# RL6678_IP_SVD register map
Vendor: Realtek
Registers are 32-bit, read-write, reset 0x0 unless marked. A register's access mark holds for its fields unless they carry their own. Offsets are from the block's base; [hi:lo] are bit positions; {n}, {i} and the like mark numbered series; 'fields as' and 'values as' point back to an identical list; <NAME> marks a mode.

## DDRPHY_REG (part 1 of 2)
Base 0x41011000
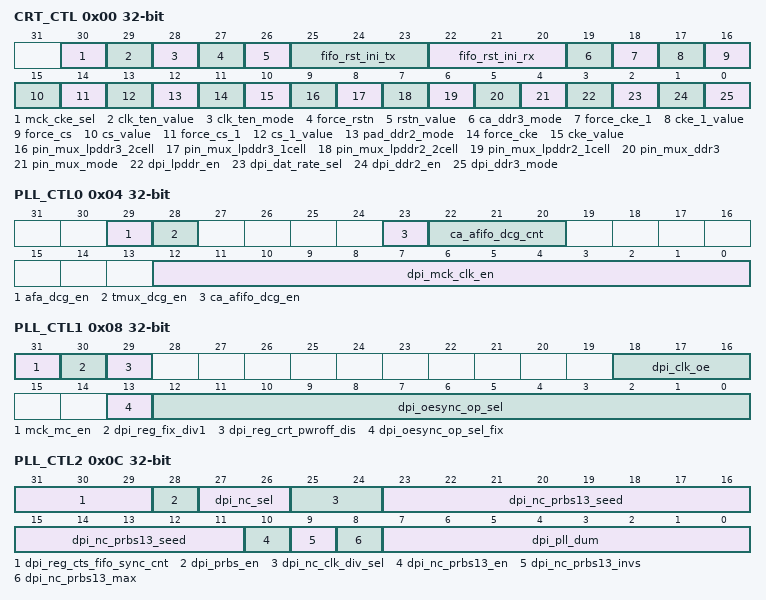
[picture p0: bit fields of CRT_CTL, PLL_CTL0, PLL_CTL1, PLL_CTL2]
0x00 CRT_CTL
  [30] mck_cke_sel — 1'b0 : mck_cke = mck_ca 1'b1 : mck_cke = mck_cs
  [29] clk_ten_value — Value for ten mode of clk
  [28] clk_ten_mode — 1 for ten mode
  [27] force_rstn — 1 for forcing PAD_DDR_RSTN value to rstn_value
  [26] rstn_value — Value of PAD_DDR_RSTN when force_rstn = 1
  [25:23] fifo_rst_ini_tx — Initial value of Tx CTS FIFO read point
  [22:20] fifo_rst_ini_rx — Initial value of Rx CTS FIFO read point
  [19] ca_ddr3_mode — Connect to command/address pad's DDR3_MODE
  [18] force_cke_1 — 1 for forcing PAD_DDR_CKE_1 value to cke_1_value
  [17] cke_1_value — Value of PAD_DDR_CKE_1 when force_cke_1 = 1
  [16] force_cs — 1 for forcing PAD_DDR_CS_N value to cs_value
  [15] cs_value — Value of PAD_DDR_CS_N when force_cs = 1
  [14] force_cs_1 — 1 for forcing PAD_DDR_CS_1_N value to cs_1_value
  [13] cs_1_value — Value of PAD_DDR_CS_1_N when force_cs_1 = 1
  [12] pad_ddr2_mode — Connect to P_PAD_DDR_VREF 0 : DDR3_MODE 1 : DDR2 MODE
  [11] force_cke — 1 for forcing PAD_DDR_CKE value to cke_value
  [10] cke_value — Value of PAD_DDR_CKE when force_cke = 1
  [9] pin_mux_lpddr3_2cell — DDR3 : b0_0001 DDR2 : b0_1000
  [8] pin_mux_lpddr3_1cell — DDR3 : b0_0001 DDR2 : b0_1000
  [7] pin_mux_lpddr2_2cell — DDR3 : b0_0001 DDR2 : b0_1000
  [6] pin_mux_lpddr2_1cell — DDR3 : b0_0001 DDR2 : b0_1000
  [5] pin_mux_ddr3 — DDR3 : b0_0001 DDR2 : b0_1000
  [4] pin_mux_mode — 1'b1 : pin_mux bypass mode 1'b0 : pin_mux mode
  [3] dpi_lpddr_en — 1'b1 : LPDDR mode enable
  [2] dpi_dat_rate_sel — 1'b0 : 2to1 mode mck_cmd = mck_mc = 1/2 DCK 1'b1 : 1to1 mode mck_cmd = mck_mc = DCK
  [1] dpi_ddr2_en — ddr2_en=1 & ddr3_mod=1 DDR2(LPDDR2) mode ddr2_en=0 & ddr3_mod=1 DDR3(LPDDR3) mode ddr2_en=0 & ddr3_mod=0 DDR4 mode
  [0] dpi_ddr3_mode — ddr2_en=1 & ddr3_mod=1 DDR2(LPDDR2) mode ddr2_en=0 & ddr3_mod=1 DDR3(LPDDR3) mode ddr2_en=0 & ddr3_mod=0 DDR4 mode
0x04 PLL_CTL0
  [29] afa_dcg_en — Rx Alpha eye calibration clock gating enable
  [28] tmux_dcg_en — Bist test mux clock gating enable
  [23] ca_afifo_dcg_en — CA AFIFO clock gating enable
  [22:20] ca_afifo_dcg_cnt — CA AFIFO clock gating count = {ca_afifo_dcg_cnt, 2'b11}
  [12:0] dpi_mck_clk_en — DDR_PHY internal clock ICG enable ck_en[12:0] :clock enable ck_en[0]: mck_ck ck_en[1]: mck_cmd ck_en[2]: mck_dqs_0 ck_en[3]: mck_dqs_1 ck_en[4]: mck_dqs_2 (No use) ck_en[5]: mck_dqs_3 (No use) ck_en[6]: mck_dq_0 ck_en[7]: mck_dq_1 ck_en[8]: mck_dq_2 (No use) ck_en[9]: mck_dq_3 (No use) ck_en[10]: mck_cs ck_en[11]: mck_cs_1 (No use) ck_en[12]: mck_ck_1 (No use)
0x08 PLL_CTL1
  [31] mck_mc_en — 0: gated mck_mc to low
  [30] dpi_reg_fix_div1 — PLL sync CLK_OE clk is fix div1(1) or div2 (0 default)
  [29] dpi_reg_crt_pwroff_dis — clk_oe to PLL is from crt table or FSM, default is from crt table.
  [18:16] dpi_clk_oe — clk_oe[2:0]: PLL clock output enable clk_oe[0]:mck_ck clk_oe[1]: mck_cmd , mck_dqs_0, mck_dqs_1, mck_dqs_2, mck_dqs_3, mck_dq_0, mck_dq_1, mck_dq_2, mck_dq_3 clk_oe[2]: mck_ck_1
  [13] dpi_oesync_op_sel_fix — free run fix clock op_sel
  [12:0] dpi_oesync_op_sel — control signal for output clock enable sync op_sel[0]:mck_ck op_sel[1]:mck_cmd op_sel[2]:mck_dqs_0 op_sel[3]:mck_dqs_1 op_sel[4]:mck_dqs_2 op_sel[5]:mck_dqs_3 op_sel[6]:mck_dq_0 op_sel[7]:mck_dq_1 op_sel[8]:mck_dq_2 op_sel[9]:mck_dq_3 op_sel[10]:mck_cs op_sel[11]:mck_cs_1 op_sel[12]:mck_ck_1
0x0C PLL_CTL2
  [31:29] dpi_reg_cts_fifo_sync_cnt — sync cts fifo tx/rx pointer,wait cycles when pweroff_rst_n sync from tx to rx
  [28] dpi_prbs_en — PLL Noise Generator Enable
  [27:26] dpi_nc_sel — PLL Noise Generator noise current control
  [25:24] dpi_nc_clk_div_sel — Noise Generator clock select
  [23:11] dpi_nc_prbs13_seed — Noise Generator PRBS SEED
  [10] dpi_nc_prbs13_en — Noise Generator enable
  [9] dpi_nc_prbs13_invs — Noise Generator PRBS INVS
  [8] dpi_nc_prbs13_max — Noise Generator PRBS MAX
  [7:0] dpi_pll_dum — dummy Register
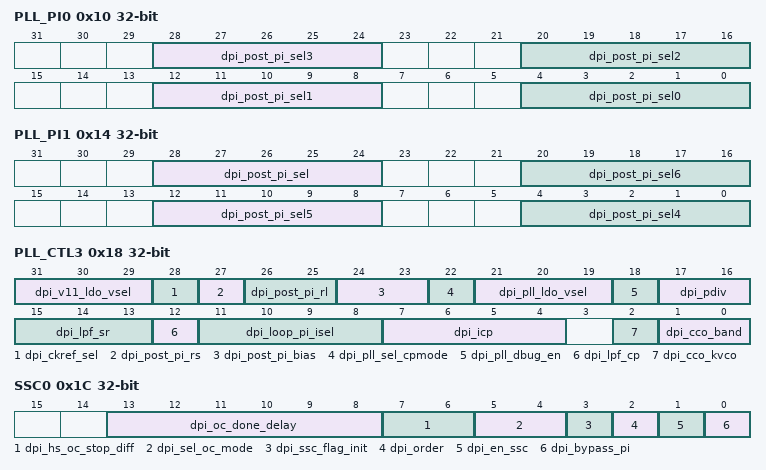
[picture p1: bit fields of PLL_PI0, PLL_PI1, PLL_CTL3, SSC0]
0x10 PLL_PI0
  [28:24] dpi_post_pi_sel3 — PLL phase select for mck_dqs_1
  [20:16] dpi_post_pi_sel2 — PLL phase select for mck_dqs_0
  [12:8] dpi_post_pi_sel1 — PLL phase select for mck_cmd
  [4:0] dpi_post_pi_sel0 — PLL phase select for mck_ck
0x14 PLL_PI1
  [28:24] dpi_post_pi_sel — PLL internal clock phase select
  [20:16] dpi_post_pi_sel6 — PLL phase select for mck_dq_0
  [12:8] dpi_post_pi_sel5 — PLL phase select for mck_dqs_3
  [4:0] dpi_post_pi_sel4 — PLL phase select for mck_dqs_2
0x18 PLL_CTL3
  [31:29] dpi_v11_ldo_vsel — Select PLL 1.0V LDO output 000: tracking digital core power 001: 0.85V; 010: 0.9V; 011: 1.0V; 100: 1.05V; 101: 1.1V 110: 1.15V 111: 1.2V
  [28] dpi_ckref_sel — Ref Clock select 1'b0: use CKREF_PAD 1'b1: use CKREF_TOP
  [27] dpi_post_pi_rs — Post PI loading cap control: 0: 112.5fF; 1: 15fF
  [26:25] dpi_post_pi_rl — Post PI RL control, changed with PLL freq: 00:0.2G~0.5G; 01:0.5G~0.8G; 10:0.8G~1.25G
  [24:23] dpi_post_pi_bias — Post PI bias current, changed with PLL freq: 00:0.2G~0.5G; 01:0.5G~0.8G; 10:0.8G~1.25G
  [22] dpi_pll_sel_cpmode — PLL charge pump mode selector, always set 1
  [21:19] dpi_pll_ldo_vsel — Select PLL 1.0V LDO output; 000: tracking core power; 001: 0.85V; 010: 0.9V; 011: 1.0V; 100: 1.05V; 101: 1.1V 110: 1.15V 111: 1.2V
  [18] dpi_pll_dbug_en — Enable PLL debug mode
  [17:16] dpi_pdiv — PLL pre-divider divisor register 00: /1; 01: /2; 10: /4; 11: /8
  [15:13] dpi_lpf_sr — PLL LPF resistor selector Register for LPF RS, combined used with REG_ICP and REG_LPF_CP to tune PLL bandwidth
  [12] dpi_lpf_cp — Register for LPF CP, combined used with REG_ICP and REG_LPF_SR to tune PLL bandwidth
  [11:8] dpi_loop_pi_isel — Select loop pi current, changed with PLL freq: 0010:0.2G~0.4G; 0011:0.4G~0.6G; 0100:0.6G~0.8G; 0101:0.8G~1G; 0110:1G~1.25G
  [7:4] dpi_icp — CP bias current control, combined used with REG_LPF_CP and REG_LPF_SR to tune PLL bandwidth
  [2] dpi_cco_kvco — PLL kvco control, combined used with REG_CCO_BAND to tune PLL freq
  [1:0] dpi_cco_band — PLL band select, combined used with REG_CCO_KVCO to tune PLL freq
0x1C SSC0
  [13:8] dpi_oc_done_delay — Delay to setting OC_DONE=1'b1 after over-clock or under-clock is done by (REG_OC_DONE_delay*Tref)
  [7:6] dpi_hs_oc_stop_diff — HS stop control 2'b00: HS OC stop at (Target_freq-2*fref) 2'b01: HS OC stop at (Target_freq-6*fref) 2'b10: HS OC stop at (Target_freq-10*fref) 2'b11: HS OC stop at (Target_freq-14*fref)
  [5:4] dpi_sel_oc_mode — Over-clock / Under-clock mode selection 2'b00: Low speed mode 2'b01: High speed mode 2'b10: Adaptive high speed mode
  [3] dpi_ssc_flag_init — SSC initial flag
  [2] dpi_order — Select 1st-order or 2nd-order SDM
  [1] dpi_en_ssc — Enable SSC function "1" : Enable "0" : Disable
  [0] dpi_bypass_pi — When no fractional divider or SSC, bypass Phase Interpolator for CMU loop 0: including PI inside the loop 1: bypass PI inside the loop
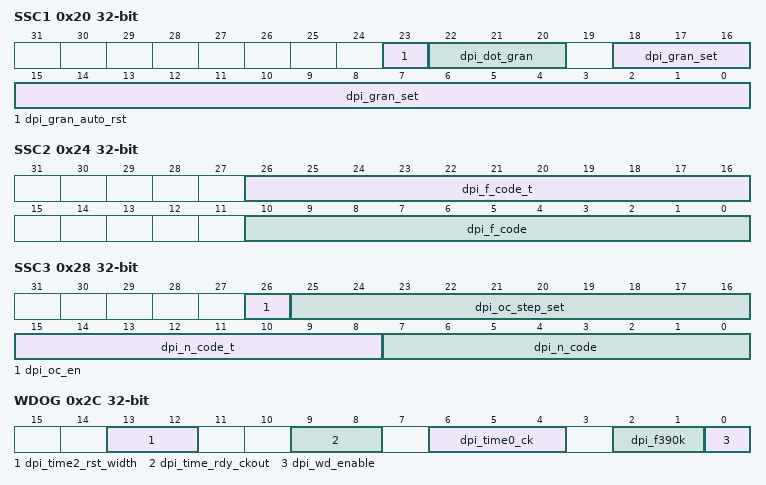
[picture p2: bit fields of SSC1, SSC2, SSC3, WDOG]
0x20 SSC1
  [23] dpi_gran_auto_rst — When FMOD transition, reset SDM
  [22:20] dpi_dot_gran — Decimal point position of GRAN 3'b000: 4.15 3'b001: 5.14 3'b010: 6.13 3'b011: 7.12 3'b100: 8.11
  [18:0] dpi_gran_set — SSC step SSC step= ((Ncode_T*2048+Fcode_T -Ncode_ssc*2048- Fcode_ssc)*33K*2^11) / ((Frequency of CKREF) * 0.5)
0x24 SSC2
  [26:16] dpi_f_code_t — Fractional code of loop divider (target Fcode of overclocking)
  [10:0] dpi_f_code — Fractional code of loop divider
0x28 SSC3
  [26] dpi_oc_en — Enable over-clock or under-clock
  [25:16] dpi_oc_step_set — Over-clock / Under-clock slope control of low speed mode
  [15:8] dpi_n_code_t — Integer code of loop divider,real divider code is (target Ncode of overclocking) CKREF=27M, REG_PDIV=2'b00, REG_BYPASS_PI=1'b0, VCO frequency=27*( REG_N_CODE [7:0] +3+ REG_F_CODE<10:0>/2048)=1.6GHz -> REG_N_CODE [7:0] =56, REG_F_CODE<10:0>=531
  [7:0] dpi_n_code — Integer code of loop divider,real divider code is CKREF=27M, REG_PDIV=2'b00, REG_BYPASS_PI=1'b0, VCO frequency=27*( REG_N_CODE [7:0] +3+ REG_F_CODE<10:0>/2048)=1.6GHz -> REG_N_CODE [7:0] =56, REG_F_CODE<10:0>=531
0x2C WDOG
  [13:12] dpi_time2_rst_width — Reset timing control (REG_TIME_RST_WIDTH x CKREF) 2'd0: 2 2'd1: 4 2'd2: 8 2'd3: 20
  [9:8] dpi_time_rdy_ckout — Clock ready timing control ( clock ready time : 2 times the value of REG_TIME_WD x CKREF + REG_TIME_RDY_CKOUT x CKTXPLL) 2'd0: 3 2'd1: 100 2'd2: 200 2'd3: 600
  [6:4] dpi_time0_ck — Watchdog timing control (clock output time: 2 times the value of REG_TIME_WD x CKREF) 3'd0: 2 3'd1: 200 3'd2: 600 3'd3: 1200 3'd4: 3000 3'd5: 6400 3'd6: 12800 3'd7: 16000
  [2:1] dpi_f390k — F390K output delay, not used
  [0] dpi_wd_enable — Enable watch dog function 0: disable Watch Dog function 1: enable Watch Dog function
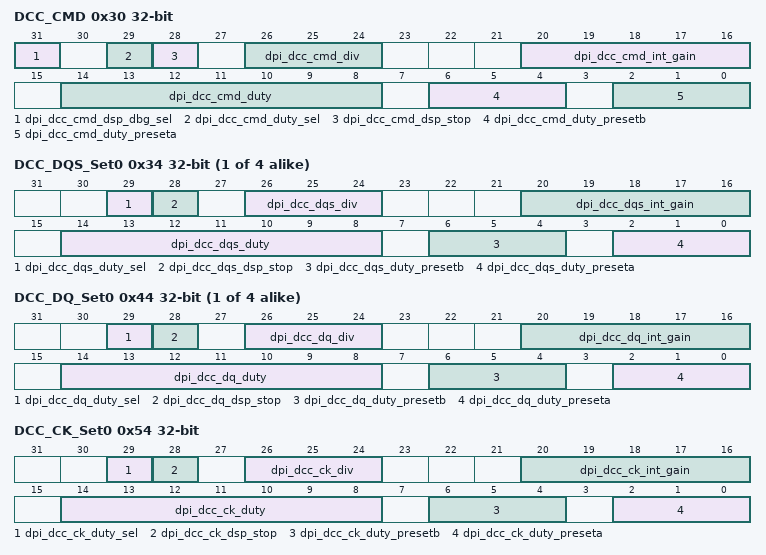
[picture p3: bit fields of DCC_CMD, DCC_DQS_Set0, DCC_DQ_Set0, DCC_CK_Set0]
0x30 DCC_CMD
  [31] dpi_dcc_cmd_dsp_dbg_sel — mck_cmd duty control debug output enable
  [29] dpi_dcc_cmd_duty_sel — mck_cmd duty control reg_dpi_dcc_cmd_duty_sel=0: output from close loop; reg_dpi_dcc_cmd_duty_sel=1: output from reg_dpi_dcc_cmd_duty[6:0]
  [28] dpi_dcc_cmd_dsp_stop — mck_cmd duty control dsp function enable
  [26:24] dpi_dcc_cmd_div — mck_cmd duty control dsp clock frequency setting: 000~111: /2^4~/2^11
  [20:16] dpi_dcc_cmd_int_gain — mck_cmd duty control close loop gain setting: 00000~11111: /2^6~/2
  [14:8] dpi_dcc_cmd_duty — mck_cmd duty control when reg_dpi_dcc_cmd_duty_sel=1'b0,output value from this register
  [6:4] dpi_dcc_cmd_duty_presetb — mck_cmd duty control DCD negitive duty preset setting
  [2:0] dpi_dcc_cmd_duty_preseta — mck_cmd duty control DCD positive duty preset setting
{0x34+4i} DCC_DQS_Set{i} (i=0..3)
  [29] dpi_dcc_dqs_duty_sel — mck_dqs duty control setting as mck_cmd setting
  [28] dpi_dcc_dqs_dsp_stop — mck_dqs duty control setting as mck_cmd setting
  [26:24] dpi_dcc_dqs_div — mck_dqs duty control setting as mck_cmd setting
  [20:16] dpi_dcc_dqs_int_gain — mck_dqs duty control setting as mck_cmd setting
  [14:8] dpi_dcc_dqs_duty — mck_dqs duty control setting as mck_cmd setting
  [6:4] dpi_dcc_dqs_duty_presetb — mck_dqs duty control setting as mck_cmd setting
  [2:0] dpi_dcc_dqs_duty_preseta — mck_dqs duty control setting as mck_cmd setting
{0x44+4i} DCC_DQ_Set{i} (i=0..3)
  [29] dpi_dcc_dq_duty_sel — mck_dq duty control setting as mck_cmd setting
  [28] dpi_dcc_dq_dsp_stop — mck_dq duty control setting as mck_cmd setting
  [26:24] dpi_dcc_dq_div — mck_dq duty control setting as mck_cmd setting
  [20:16] dpi_dcc_dq_int_gain — mck_dq duty control setting as mck_cmd setting
  [14:8] dpi_dcc_dq_duty — mck_dq duty control setting as mck_cmd setting
  [6:4] dpi_dcc_dq_duty_presetb — mck_dq duty control setting as mck_cmd setting
  [2:0] dpi_dcc_dq_duty_preseta — mck_dq duty control setting as mck_cmd setting
0x54 DCC_CK_Set0
  [29] dpi_dcc_ck_duty_sel — mck_ck duty control setting as mck_cmd setting
  [28] dpi_dcc_ck_dsp_stop — mck_ck duty control setting as mck_cmd setting
  [26:24] dpi_dcc_ck_div — mck_ck duty control setting as mck_cmd setting
  [20:16] dpi_dcc_ck_int_gain — mck_ck duty control setting as mck_cmd setting
  [14:8] dpi_dcc_ck_duty — mck_ck duty control setting as mck_cmd setting
  [6:4] dpi_dcc_ck_duty_presetb — mck_ck duty control setting as mck_cmd setting
  [2:0] dpi_dcc_ck_duty_preseta — mck_ck duty control setting as mck_cmd setting
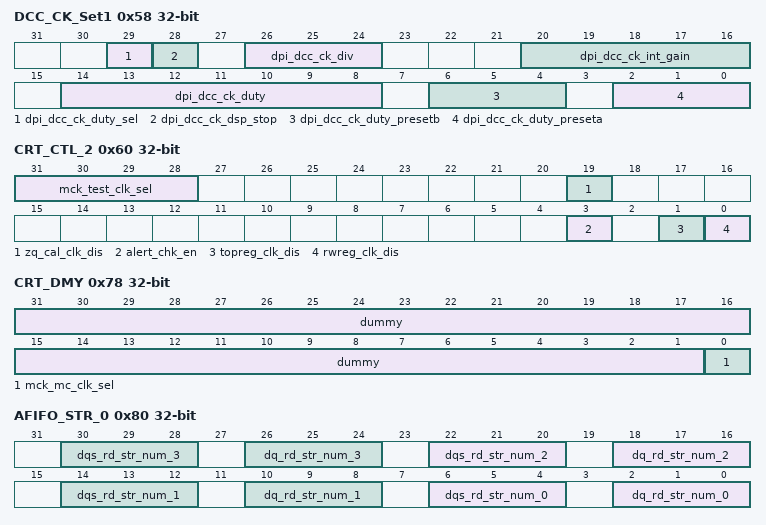
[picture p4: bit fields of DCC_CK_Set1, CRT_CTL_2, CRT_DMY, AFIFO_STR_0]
0x58 DCC_CK_Set1
  fields as DCC_CK_Set0
0x60 CRT_CTL_2
  [31:28] mck_test_clk_sel — to PAD MP test debug clock select (PLL output clock /32 to debug port)
  [19] zq_cal_clk_dis — set 1 to disable zq calibration clock
  [3] alert_chk_en — set 1 to enable alert pad security check
  [1] topreg_clk_dis — set 1 to disable regif clock of top
  [0] rwreg_clk_dis — set 1 to disable regif clock of rw_blk
0x78 CRT_DMY
  [31:1] dummy — Dummy Registers
  [0] mck_mc_clk_sel — Select clock source of mck_mc 1'b0: select mck_cmd 1'b1: select PLL internal clock
0x7C CRT_DMY1
  [31:0] dummy — Dummy Registers
0x80 AFIFO_STR_0
  [8n+6:8n+4] dqs_rd_str_num_{n} (n=0..3) — slice{n} DQS TX FIFO threshold setting
  [8n+2:8n] dq_rd_str_num_{n} (n=0..3) — slice{n} DQ TX FIFO threshold setting
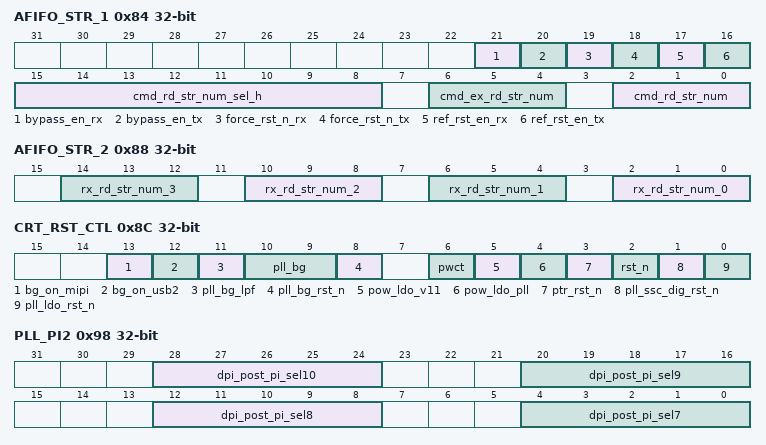
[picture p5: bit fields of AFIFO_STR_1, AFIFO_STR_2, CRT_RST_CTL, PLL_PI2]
0x84 AFIFO_STR_1
  [21] bypass_en_rx — Bypass RX FIFO
  [20] bypass_en_tx — Bypass TX FIFO
  [19] force_rst_n_rx — Force reset RX FIFO
  [18] force_rst_n_tx — Force reset TX FIFO
  [17] ref_rst_en_rx — Enable reset RX FIFO during refresh
  [16] ref_rst_en_tx — Enable reset TX FIFO during refresh
  [15:8] cmd_rd_str_num_sel_h — [15] : PAD cke_1 [14] : PAD alert_1 [13] : PAD par_1 [12] : PAD ddr4_cke [11] : PAD act_n [10] : PAD bg0 [09] : PAD par [08] : PAD ten
  [6:4] cmd_ex_rd_str_num — CMD TX FIFO threshold setting (Another, Select by cmd_rd_str_num_sel)
  [2:0] cmd_rd_str_num — CMD TX FIFO threshold setting
0x88 AFIFO_STR_2
  [4n+2:4n] rx_rd_str_num_{n} (n=0..3) — slice{n} RX FIFO threshold setting
0x8C CRT_RST_CTL
  [13] bg_on_mipi — Bandgap MIPI current enable
  [12] bg_on_usb2 — Bandgap USB2 current enable
  [11] pll_bg_lpf — Bandgap low pass filter
  [10:9] pll_bg — Bandgap enable mode
  [8] pll_bg_rst_n — DDRPLL bandgap reset, low active
  [6] pwct — 1'b0: 3.3V power cut
  [5] pow_ldo_v11 — LDO for CK PAD 下面的AVDD1V為外灌的1V 开机时: 如果AVDD33先来,VD10A_DLL后来,在VD10A_DL没电时,pll_ldo_rst_n经过CDMCELL(吃AVDD1V)为0,LDO power down 且斷開外灌VD10A_DLL 如果AVDD1V先来,AVDD33后来,LDO处于power down状态,core power也无电,外灌1V的power switch也断开 Standby:pll_ldo_rst_n =0,LDO关闭且外灌断开; AVDD1V 有电,DVDD和AVDD3V无电,pll_ldo_rst_n 在经过CDMCELL时被DVDD POR卡住为0, LDO 无电且外灌断开,不会有漏电, Normal:pll_ldo_rst_n =1,REG_POW_LDO_V11=0 or 1不会出现外灌与LDO并联的情况; reg_pow_ ldo_v11 pll_ldo_rst_n 0 0 LDO power down 且外灌1V和LDO output间power switch断开 0 1 选外灌,此时 LDO 是power down 1 0 LDO power down 且外灌1V和LDO output间power switch断开 1 1 选LDO, 外灌的1V会给其他电路
  [4] pow_ldo_pll — LDO for PLL CCO,控制和LDO_V11 控制相同 reg_pow_ldo_pll pll_ldo_rst_n 0 0 LDO power down 且外灌1V和LDO output间power switch断开 0 1 选外灌,此时 LDO 是power down 1 0 LDO power down 且外灌1V和LDO output间power switch断开 1 1 选LDO, 外灌的1V会给其他电路
  [3] ptr_rst_n — reset 3-point and dqsen calibration results, low active
  [2] rst_n — reset all digital circuits, except 3-point calibration, dqsen calibration, and PLL SSC block, low active
  [1] pll_ssc_dig_rst_n — reset PLL SSC circuit, low active
  [0] pll_ldo_rst_n — DDRPLL LDO reset, low active
0x94 AFIFO_STR_SEL
  [31:0] cmd_rd_str_num_sel — CMD TX FIFO threshold value select 1'b0 : cmd_rd_str_num 1'b1 : cmd_ex_rd_str_num [31] : PAD alert [30] : PAD ddr4_cs_n [29] : PAD cs_n_1 [28] : PAD cs_n [27] : PAD odt [26] : PAD cke [25] : PAD cas_n [24] : PAD ras_n [23] : PAD we_n [22] : PAD reset_n, [21:19] : PAD Bank[2:0] [18:17] : PAD Adr_ext[5:4] [16: 0] : PAD Address[16:0]
0x98 PLL_PI2
  [28:24] dpi_post_pi_sel10 — PLL phase select for mck_cs
  [20:16] dpi_post_pi_sel9 — PLL phase select for mck_dq_3
  [12:8] dpi_post_pi_sel8 — PLL phase select for mck_dq_2
  [4:0] dpi_post_pi_sel7 — PLL phase select for mck_dq_1
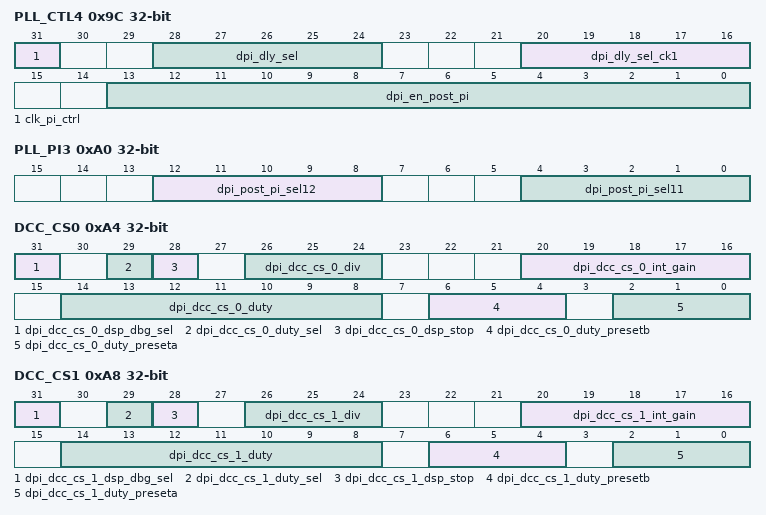
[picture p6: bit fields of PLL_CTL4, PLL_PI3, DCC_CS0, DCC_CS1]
0x9C PLL_CTL4
  [31] clk_pi_ctrl — 0: PI of CLK1X/CLK1XB is controlled by dpi_post_pi_sel* 1: PI of CLK1X/CLK1XB is controlled by dpi_post_pi_sel* and fw_set_wr_dly
  [28:24] dpi_dly_sel — Delay chain selection for CLK1X_0 and CLK1XB_0
  [20:16] dpi_dly_sel_ck1 — Delay chain selection for CLK1X_12 and CLK1XB_12(No use)
  [13:0] dpi_en_post_pi — Enable PLL phase selector post_pi[0]: mck_ck post_pi[1]: mck_cmd post_pi[2]: mck_dqs_0 post_pi[3]: mck_dqs_1 post_pi[4]: mck_dqs_2 post_pi[5]: mck_dqs_3 post_pi[6]: mck_dq_0 post_pi[7]: mck_dq_1 post_pi[8]: mck_dq_2 post_pi[9]: mck_dq_3 post_pi[10]: mck_cs post_pi[11]: mck_cs_1 post_pi[12]: PLL internal clock
0xA0 PLL_PI3
  [12:8] dpi_post_pi_sel12 — PLL phase select for mck_ck_1
  [4:0] dpi_post_pi_sel11 — PLL phase select for mck_cs_1
0xA4 DCC_CS0
  [31] dpi_dcc_cs_0_dsp_dbg_sel — mck_cs0 duty control debug output enable
  [29] dpi_dcc_cs_0_duty_sel — mck_cs0 duty control reg_dpi_dcc_cs_duty_sel=0: output from close loop; reg_dpi_dcc_cs_duty_sel=1: output from reg_dpi_dcc_cs_duty[6:0]
  [28] dpi_dcc_cs_0_dsp_stop — mck_cs0 duty control dsp function enable
  [26:24] dpi_dcc_cs_0_div — mck_cs0 duty control dsp clock frequency setting: 000~111: /2^4~/2^11
  [20:16] dpi_dcc_cs_0_int_gain — mck_cs0 duty control close loop gain setting: 00000~11111: /2^6~/2
  [14:8] dpi_dcc_cs_0_duty — mck_cs0 duty control when reg_dpi_dcc_cs_duty_sel=1'b0, output value from this register
  [6:4] dpi_dcc_cs_0_duty_presetb — mck_cs0 duty control DCD negitive duty preset setting
  [2:0] dpi_dcc_cs_0_duty_preseta — mck_cs0 duty control DCD positive duty preset setting
0xA8 DCC_CS1
  [31] dpi_dcc_cs_1_dsp_dbg_sel — mck_cs1 duty control debug output enable
  [29] dpi_dcc_cs_1_duty_sel — mck_cs1 duty control reg_dpi_dcc_cs_duty_sel=0: output from close loop; reg_dpi_dcc_cs_duty_sel=1: output from reg_dpi_dcc_cs_duty[6:0]
  [28] dpi_dcc_cs_1_dsp_stop — mck_cs1 duty control dsp function enable
  [26:24] dpi_dcc_cs_1_div — mck_cs1 duty control dsp clock frequency setting: 000~111: /2^4~/2^11
  [20:16] dpi_dcc_cs_1_int_gain — mck_cs1 duty control close loop gain setting: 00000~11111: /2^6~/2
  [14:8] dpi_dcc_cs_1_duty — mck_cs1 duty control when reg_dpi_dcc_cs_duty_sel=1'b0, output value from this register
  [6:4] dpi_dcc_cs_1_duty_presetb — mck_cs1 duty control DCD negitive duty preset setting
  [2:0] dpi_dcc_cs_1_duty_preseta — mck_cs1 duty control DCD positive duty preset setting
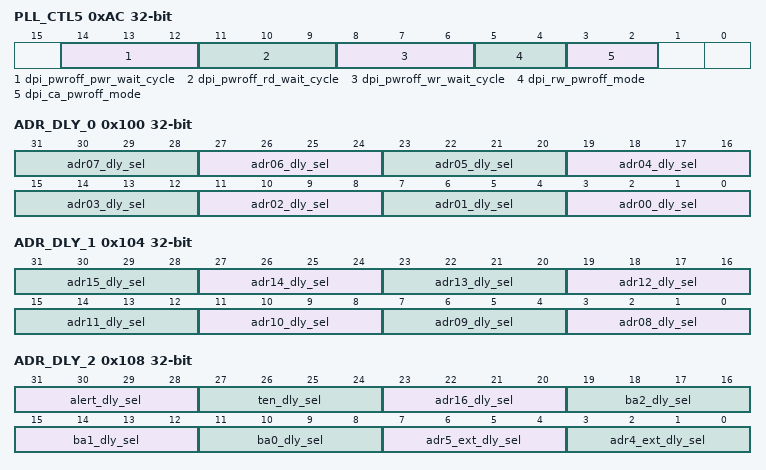
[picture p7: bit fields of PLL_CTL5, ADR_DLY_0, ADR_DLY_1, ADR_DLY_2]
0xAC PLL_CTL5
  [14:12] dpi_pwroff_pwr_wait_cycle — clk on wait cycle when dfi_pwr is 0 0: wait 0 cycle 1: wait 8 mck_mc cycles 2: wait 8x2 mck_mc cycles 3: wait 8x3 mck_mc cycles,etc.
  [11:9] dpi_pwroff_rd_wait_cycle — clk on wait cycle when RD is end, 0: wait 1 mck_mc cycle 1: wait 8 mck_mc cycles 2: wait 8x2 mck_mc cycles 3: wait 8x3 mck_mc cycles,etc.
  [8:6] dpi_pwroff_wr_wait_cycle — clk on wait cycle when WR is end 0: wait 1 mck_mc cycle 1: wait 8 mck_mc cycles 2: wait 8x2 mck_mc cycles 3: wait 8x3 mck_mc cycles,etc.
  [5:4] dpi_rw_pwroff_mode — rw blk clocks gating mode: 0: no gating 1: no REF and dfi_pwr = 0, 2: no REF/WR/RD 3: no REF and (no WR/RD or dfi_pwr = 0)
  [3:2] dpi_ca_pwroff_mode — CMD/ADDR clocks gating mode: 0: no gating 1: gating DPI clock when dfi_pwr = 0 2: gating DPI clock and DCK when dfi_pwr = 0 3: reserved
0x100 ADR_DLY_0
  [4n+3:4n] adr{n:02}_dly_sel (n=0..7) — Address[{n}] delay chain control
0x104 ADR_DLY_1
  [4n-29:4n-32] adr{n:02}_dly_sel (n=8..15) — Address[{n}] delay chain control
0x108 ADR_DLY_2
  [31:28] alert_dly_sel — Alert delay chain control
  [27:24] ten_dly_sel — Ten delay chain control ( for DDR4 BG0 use)
  [23:20] adr16_dly_sel — Address[16] delay chain control (for DDR4 A1 used)
  [19:16] ba2_dly_sel — BANK[2] delay chain control
  [15:12] ba1_dly_sel — BANK[1] delay chain control
  [11:8] ba0_dly_sel — BANK[0] delay chain control
  [7:4] adr5_ext_dly_sel — Extent address[5] delay chain control
  [3:0] adr4_ext_dly_sel — Extent address[4] delay chain control
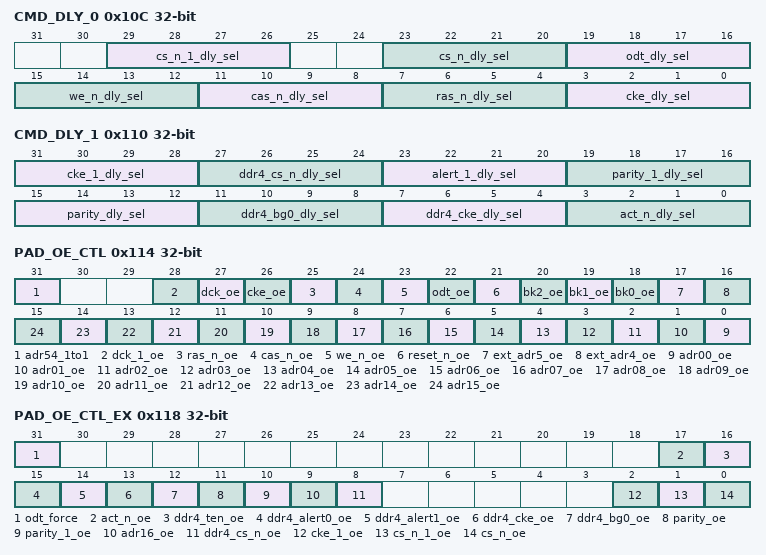
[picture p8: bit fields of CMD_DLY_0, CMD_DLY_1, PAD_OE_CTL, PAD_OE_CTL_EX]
0x10C CMD_DLY_0
  [29:26] cs_n_1_dly_sel — CS_N_1 delay chain control
  [23:20] cs_n_dly_sel — CS_N delay chain control
  [19:16] odt_dly_sel — ODT delay chain control
  [15:12] we_n_dly_sel — WE_N delay chain control
  [11:8] cas_n_dly_sel — CAS_N delay chain control
  [7:4] ras_n_dly_sel — RAS_N delay chain control
  [3:0] cke_dly_sel — CKE delay chain control
0x110 CMD_DLY_1
  [31:28] cke_1_dly_sel — CKE_1 delay chain control
  [27:24] ddr4_cs_n_dly_sel — DDR4_CS_N delay chain control
  [23:20] alert_1_dly_sel — ALERT_1 delay chain control
  [19:16] parity_1_dly_sel — PARITY_1 delay chain control
  [15:12] parity_dly_sel — PARITY delay chain control
  [11:8] ddr4_bg0_dly_sel — DDR4_BG0 delay chain control
  [7:4] ddr4_cke_dly_sel — DDR4_CKE delay chain control
  [3:0] act_n_dly_sel — ACT_N delay chain control
0x114 PAD_OE_CTL
  [31] adr54_1to1 — Address[5:4] OCD control: 1: controlled by ocd_set_5 (1 -> 1) 0: controlled by ocd_set_4 (1 -> 2)
  [28] dck_1_oe — Output enable of DCK_1
  [27] dck_oe — Output enable of DCK
  [26] cke_oe — Output enable of CKE
  [25] ras_n_oe — Output enable of RAS_N
  [24] cas_n_oe — Output enable of CAS_N
  [23] we_n_oe — Output enable of WE_N
  [22] odt_oe — Output enable of ODT
  [21] reset_n_oe — Output enable of Reset_N
  [20] bk2_oe — Output enable of BANK[2]
  [19] bk1_oe — Output enable of BANK[1]
  [18] bk0_oe — Output enable of BANK[0]
  [17] ext_adr5_oe — Output enable of Extent address[5]
  [16] ext_adr4_oe — Output enable of Extent address[4]
  [n] adr{n:02}_oe (n=0..15) — Output enable of address[{n:02}]
0x118 PAD_OE_CTL_EX
  [31] odt_force — 1 for forcing ODT to high when do write leveling
  [17] act_n_oe — Output enable of ACTN
  [16] ddr4_ten_oe — Output enable of DDR4 TEN
  [15] ddr4_alert0_oe — Output enable of DDR4 ALERT_0
  [14] ddr4_alert1_oe — Output enable of DDR4 ALERT_1
  [13] ddr4_cke_oe — Output enable of DDR4 CKE
  [12] ddr4_bg0_oe — Ouput enable of DDR4 BG0
  [11] parity_oe — Ouput enable of PARITY
  [10] parity_1_oe — Ouput enable of PARITY_1
  [9] adr16_oe — Ouput enable of A16
  [8] ddr4_cs_n_oe — Output enable of DDR4 DCS_N
  [2] cke_1_oe — Output enable of CKE_1
  [1] cs_n_1_oe — Output enable of DCS_N_1
  [0] cs_n_oe — Output enable of DCS_N
0x11C PAD_ALERT_0_SEL_0
  [31:0] alert_sel_0 — ALERT enable of { DDR4 ALERT_1, DDR4 CKE, DDR4 BG0, PARITY, PARITY_1, CKE, RAS_N, CAS_N, WE_N, ODT, BANK[2], BANK[1], BANK[0], Extent address[5], Extent address[4], Address[16:0]}
0x120 PAD_ALERT_0_SEL_1
  [3:0] alert_sel_1 — ALERT enable of { CKE_1, ACTN, DDR4 TEN, DDR4 ALERT_0}
0x124 PAD_ALERT_1_SEL_0
  fields as PAD_ALERT_0_SEL_0
0x128 PAD_ALERT_1_SEL_1
  fields as PAD_ALERT_0_SEL_1
0x12C PAD_IDDQ
  [11:0] iddq — For power-down input comparator bit0: dqs[0] bit1: dqs_n[0] ...... bit6: dqs[3] bit7: dqs_n[3] bit8: dq[7:0] ...... bit11: dq[31:24]
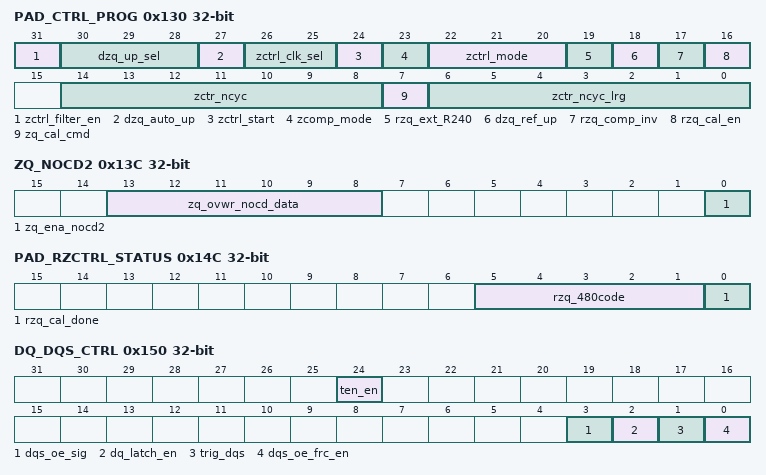
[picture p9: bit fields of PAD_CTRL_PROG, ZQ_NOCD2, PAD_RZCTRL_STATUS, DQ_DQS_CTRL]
0x130 PAD_CTRL_PROG
  [31] zctrl_filter_en — ZQ Calibration filter enable
  [30:28] dzq_up_sel — Enable auto update OCD / ODT set0~set7
  [27] dzq_auto_up — Auto update TTFP, TTCP, TTFN, TTCN, PT, NT, E2 of dq31~dq0 and dqs3~dqs0 when calibration done.
  [26:25] zctrl_clk_sel — Zctrl clock select 00: zclk/16 01: zclk/32 10: zclk/64 11: zclk/128
  [24] zctrl_start — Calibration start
  [23] zcomp_mode — 1'b0 : catch first result 1'b1 : catch last result
  [22:20] zctrl_mode — 3'h0 : NOCD(CAL00)+POCD(CAL01)+ NODT(CAL10)+PODT(CAL11) 3'h1 : NOCD(CAL00) only 3'h2 : POCD(CAL01) only 3'h3 : NODT(CAL10) only 3'h4 : PODT(CAL11) only
  [19] rzq_ext_R240 — 1: select external calibration resistor 0: select internal calibration resistor
  [18] dzq_ref_up — Auto update TTFP, TTCP, TTFN, TTCN, PT, NT, E2 of dq31~dq0 and dqs3~dqs0 during refresh
  [17] rzq_comp_inv — Invert comp polarity
  [16] rzq_cal_en — Enable resistor 480Ω calibration
  [14:8] zctr_ncyc — ZQ calibration PRE POCD/NODT/PODT null cycle (unit : zclk_p)
  [7] zq_cal_cmd — for ZQ PAD
  [6:0] zctr_ncyc_lrg — ZQ calibration PRE NOCD null cycle (unit : zclk_p)
0x13C ZQ_NOCD2
  [13:8] zq_ovwr_nocd_data — when zctrl_mode = 2 or 4 (POCD/ PDOT only) ZQ _PAD NOCD = zq_ovwr_nocd_data
  [0] zq_ena_nocd2 — directly control ZQ module NOCD2 enable
0x140 PAD_ZCTRL_STATUS
  [31:0] zctrl_status — Zctrl execution status xxx_sts : 2'b00 : no error 2'b01 : overflow error 2'b10 : underflow error 2'b11 : calibration in progress [31] : zctrl_done [30] : rzq480_done [29:24] : Reserved [23:22] : Reserved [21:20] : rzq480_sts [19:18] : Reserved [17:16] : nocd2_sts [15:14] : Reserved [13:12] : podt_sts [11:10] : Reserved [ 9: 8] : nodt_sts [ 7: 6] : Reserved [ 5: 4] : pocd_sts [ 3: 2] : Reserved [ 1: 0] : nocd_sts
0x144 PAD_ZCTRL_RESULT ro
  [31:0] zctrl_result — Zctrl execution result [31:30] : Reserved [29:24] : PODT [23] : Reserved [22:16] : NODT [15:14] : Reserved [13: 8] : POCD [ 7] : Reserved [ 6: 0] : NOCD
0x148 PAD_ZCTRL_RESULT_D ro
  [31:0] zctrl_result_dbg — Zctrl execution result [31: 8] : Reserved [ 7] : Reserved [ 6: 0] : NOCD2
0x14C PAD_RZCTRL_STATUS access per field
  [5:1] rzq_480code rw — Control resistor value
  [0] rzq_cal_done ro — Resistor 480Ω calibration done
0x150 DQ_DQS_CTRL access per field
  [24] ten_en rw — 1 for ten enable
  [3] dqs_oe_sig rw — DQS OE
  [2] dq_latch_en rw — Capture DQ bus enable
  [1] trig_dqs wo — dqs 1T pulse trigger (one cycle pulse, HW auto clear).
  [0] dqs_oe_frc_en rw — when set to 1, oe of dqs pad state will depend on the vaule of bit[3] (dqs_oe_sig)
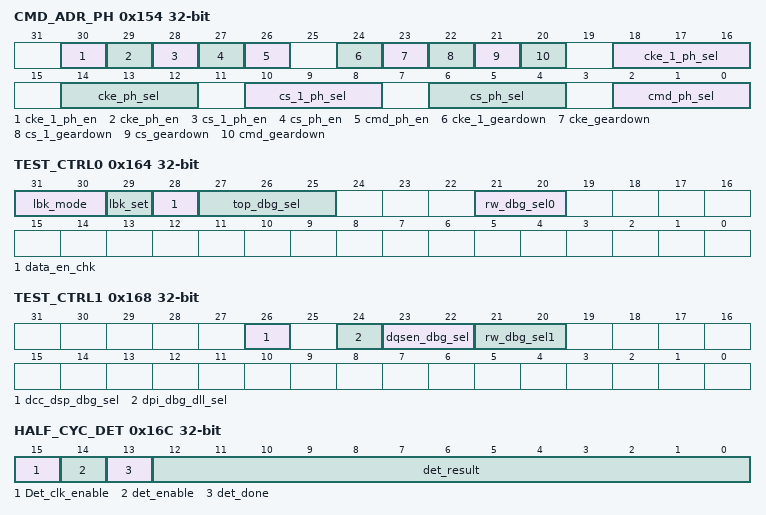
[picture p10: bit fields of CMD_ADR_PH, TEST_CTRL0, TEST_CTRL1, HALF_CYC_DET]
0x154 CMD_ADR_PH
  [30] cke_1_ph_en — CKE_1 output delay enable
  [29] cke_ph_en — CKE output delay enable
  [28] cs_1_ph_en — CS_1 output delay enable
  [27] cs_ph_en — CS output delay enable
  [26] cmd_ph_en — Command output delay enable
  [24] cke_1_geardown — 0 : normal; 1 is gear down
  [23] cke_geardown — 0 : normal; 1 is gear down
  [22] cs_1_geardown — 0 : normal; 1 is gear down
  [21] cs_geardown — 0 : normal; 1 is gear down
  [20] cmd_geardown — 0 : normal; 1 is gear down
  [18:16] cke_1_ph_sel — CKE_1 output delay : 3'b000 : delay 1 cycle 3'b001 : delay 2 cycles 3'b010 : delay 3 cycles 3'b011 : delay 4 cycles ............... 3'b111 : delay 8 cycles
  [14:12] cke_ph_sel — CKE output delay : 3'b000 : delay 1 cycle 3'b001 : delay 2 cycles 3'b010 : delay 3 cycles 3'b011 : delay 4 cycles ............... 3'b111 : delay 8 cycles
  [10:8] cs_1_ph_sel — CS_1 output delay : 3'b000 : delay 1 cycle 3'b001 : delay 2 cycles 3'b010 : delay 3 cycles 3'b011 : delay 4 cycles ............... 3'b111 : delay 8 cycles
  [6:4] cs_ph_sel — CS output delay : 3'b000 : delay 1 cycle 3'b001 : delay 2 cycles 3'b010 : delay 3 cycles 3'b011 : delay 4 cycles ............... 3'b111 : delay 8 cycles
  [2:0] cmd_ph_sel — Command output delay : 3'b000 : delay 1 cycle 3'b001 : delay 2 cycles 3'b010 : delay 3 cycles 3'b011 : delay 4 cycles ............... 3'b111 : delay 8 cycles
0x158 DQ_PAT_IN0 ro
  [31:0] dq_pat_in0 — Read data from DDR when dq_latch_en is high (dq_pat_in0 = 0 when dq_latch_en is low) [31] dq31 .............. [1] dq01 [0] dq00
0x15C DQ_PAT_IN1 ro
  [3:0] dq_pat_in1 — Read data from DDR when dq_latch_en is high (dq_pat_in1 = 0 when dq_latch_en is low) [3] dbi3 [2] dbi2 [1] dbi1 [0] dbi0
0x160 WRLVL_DQS_DATA ro
  [7:0] wrlvl_dqsdata — Read data from DDR when ten_en is high (wrlvl_dqsdata = 0 when ten_en is low) [7] dqsb_3 [6] dqs_3 [5] dqsb_2 [4] dqs_2 [3] dqsb_1 [2] dqs_1 [1] dqsb_0 [0] dqs_0
0x164 TEST_CTRL0
  [31:30] lbk_mode — Self-loopback mode [00] self-loopback mode disable [01] self-loopback bypass pad [10] self-loopback through pad [11] self-loopback dfi signals
  [29] lbk_set — Set below registers for loopback test automatically: rd_dly_pos_sel_* = 5'h0, rd_dly_neg_sel_* = 5'h0, cal_set_mode = 2'b11, rst_fifo_mode = 2'b10, data_pre = 0
  [28] data_en_chk — 1: Check burst length of dfi_wr/rddata_en, and return check results to data_en_err_type.
  [27:25] top_dbg_sel — Debug selection for top
  [21:20] rw_dbg_sel0 — Debug selection for read / write slice top
0x168 TEST_CTRL1
  [26] dcc_dsp_dbg_sel — Debug selection for all DCC DSP
  [24] dpi_dbg_dll_sel — Debug selection for dpi_debug_dll[63:0] to read-only register
  [23:22] dqsen_dbg_sel — Debug selection for dqsen_dbg[31:0] to read-only register
  [21:20] rw_dbg_sel1 — Debug selection for read / write slice top
0x16C HALF_CYC_DET access per field
  [15] Det_clk_enable rw — Half cycle delay tap detector clk enable. Need first enable before det_enable.
  [14] det_enable rw — Half cycle delay tap detector enable
  [13] det_done rw — Half cycle delay tap detector done
  [12:0] det_result ro — the number of delay tap
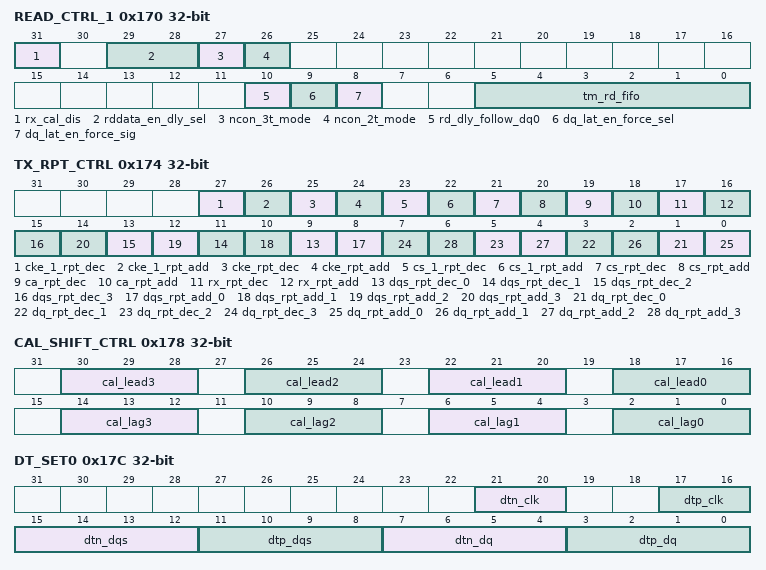
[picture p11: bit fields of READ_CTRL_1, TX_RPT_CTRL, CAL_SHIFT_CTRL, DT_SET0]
0x170 READ_CTRL_1
  [31] rx_cal_dis — 1 :RX calibration disable Should set fw_set_rd_dly to active the function due to double-buffer design. In order to prevent the te/delta/vref setting from restoring to FW default value, please make sure the following registers should be set to 0 before triggering fw_set_rd_dly.. fw_dqsen_ftun_upd =0 (in rw_spec) fw_rd_delta_upd =0 (in rw_spec) fw_rd_te_upd =0 (in rw_spec) vr_upd =0 (in dll_spec)
  [29:28] rddata_en_dly_sel — Select dfi_rddata_en_p* delay cycles in DPI. 00: delay 0T 01: delay 4T 10: delay 6T 11: delay 8T
  [27] ncon_3t_mode — for PUPD3 non-con 3T mode (ie, 4T margin for tm_dqs_en)
  [26] ncon_2t_mode — for PUPD3 non-con 2T mode (ie, 3T margin for tm_dqs_en)
  [10] rd_dly_follow_dq0 — When this field is set to 1, FW can program read delay chain (dq31 ~ dq0) setting by dq0 (1800_006C ~ 1800_00C8)
  [9] dq_lat_en_force_sel — dq latch control (in receive_1st & n/p_FIFO) 0 : controlled by read command 1: controlled by dq_lat_en_force_sig
  [8] dq_lat_en_force_sig — If set dq_lat_en_force_sel, dq latch enable is controlled by dq_lat_en_force_sig.
  [5:0] tm_rd_fifo — read FIFO latency from read command 2T DCK unit for 2to1 mode 1T DCK unit for 1to1 mode
0x174 TX_RPT_CTRL
  [27] cke_1_rpt_dec — set 1'b1 per time : delay 1T (auto clear 0)
  [26] cke_1_rpt_add — set 1'b1 per time : lead 1T (auto clear 0)
  [25] cke_rpt_dec — set 1'b1 per time : delay 1T (auto clear 0)
  [24] cke_rpt_add — set 1'b1 per time : lead 1T (auto clear 0)
  [23] cs_1_rpt_dec — set 1'b1 per time : delay 1T (auto clear 0)
  [22] cs_1_rpt_add — set 1'b1 per time : lead 1T (auto clear 0)
  [21] cs_rpt_dec — set 1'b1 per time : delay 1T (auto clear 0)
  [20] cs_rpt_add — set 1'b1 per time : lead 1T (auto clear 0)
  [19] ca_rpt_dec — set 1'b1 per time : delay 1T (auto clear 0)
  [18] ca_rpt_add — set 1'b1 per time : lead 1T (auto clear 0)
  [17] rx_rpt_dec — set 1'b1 per time : delay 1T (auto clear 0)
  [16] rx_rpt_add — set 1'b1 per time : lead 1T (auto clear 0)
  [2n+9] dqs_rpt_dec_{n} (n=0..3) — set 1'b1 per time : delay 1T (auto clear 0)
  [2n+8] dqs_rpt_add_{n} (n=0..3) — set 1'b1 per time : lead 1T (auto clear 0)
  [2n+1] dq_rpt_dec_{n} (n=0..3) — set 1'b1 per time : delay 1T (auto clear 0)
  [2n] dq_rpt_add_{n} (n=0..3) — set 1'b1 per time : lead 1T (auto clear 0)
0x178 CAL_SHIFT_CTRL
  [30:28] cal_lead3 — Central point shift right control when 3-point calibration result is lead[3] = 1.
  [26:24] cal_lead2 — Central point shift right control when 3-point calibration result is lead[2] = 1.
  [22:20] cal_lead1 — Central point shift right control when 3-point calibration result is lead[1] = 1.
  [18:16] cal_lead0 — Central point shift right control when 3-point calibration result is lead[0] = 1. [2's complement format] (sign, 2.0) 000: 0 001: 1 010: 2 011: 3 [Note] lead[3] <- lead[2] <- lead[1] <- lead[0] <- central
  [14:12] cal_lag3 — Central point shift left control when 3-point calibration result is lag[3] = 1.
  [10:8] cal_lag2 — Central point shift left control when 3-point calibration result is lag[2] = 1.
  [6:4] cal_lag1 — Central point shift left control when 3-point calibration result is lag[1] = 1.
  [2:0] cal_lag0 — Central point shift left control when 3-point calibration result is lag[0] = 1. [2's complement format] (sign, 2.0) 111: -1 110: -2 101: -3 100: -4 [Note] central -> lag[0] -> lag[1] -> lag[2] -> lag[3]
0x17C DT_SET0
  [21:20] dtn_clk — [0]: DTN of CLK, [1]: DTN of CLK_1
  [17:16] dtp_clk — [0]: DTP of CLK, [1]: DTP of CLK_1
  [15:12] dtn_dqs — [0]: DTN of DQS0, [1]: DTN of DQS1, [2]: DTN of DQS2, [3]: DTN of DQS3
  [11:8] dtp_dqs — [0]: DTP of DQS0, [1]: DTP of DQS1, [2]: DTP of DQS2, [3]: DTP of DQS3
  [7:4] dtn_dq — [0]: DTN of DQ[7:0], [1]: DTN of DQ[15:8], [2]: DTN of DQ[23:16], [3]: DTN of DQ[31:24]
  [3:0] dtp_dq — [0]: DTP of DQ[7:0], [1]: DTP of DQ[15:8], [2]: DTP of DQ[23:16], [3]: DTP of DQ[31:24] [Note1] DTP: high-period input duty trimming [Note2] DTN: low-period input duty trimming
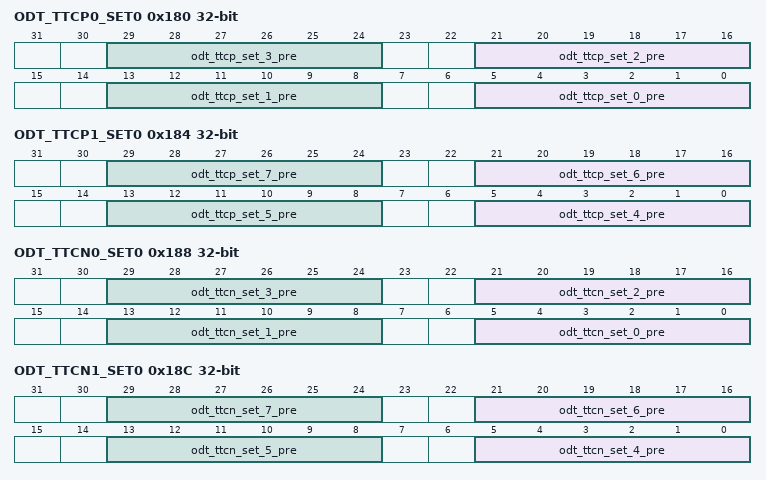
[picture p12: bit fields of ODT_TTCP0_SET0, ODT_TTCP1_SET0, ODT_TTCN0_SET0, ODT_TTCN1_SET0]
0x180 ODT_TTCP0_SET0
  [8n+5:8n] odt_ttcp_set_{n}_pre (n=0..3) — P-ODT coarse trimming set_{n}.
0x184 ODT_TTCP1_SET0
  [8n-27:8n-32] odt_ttcp_set_{n}_pre (n=4..7) — P-ODT coarse trimming set_{n}.
0x188 ODT_TTCN0_SET0
  [8n+5:8n] odt_ttcn_set_{n}_pre (n=0..3) — N-ODT coarse trimming set_{n}.
0x18C ODT_TTCN1_SET0
  [8n-27:8n-32] odt_ttcn_set_{n}_pre (n=4..7) — N-ODT coarse trimming set_{n}.
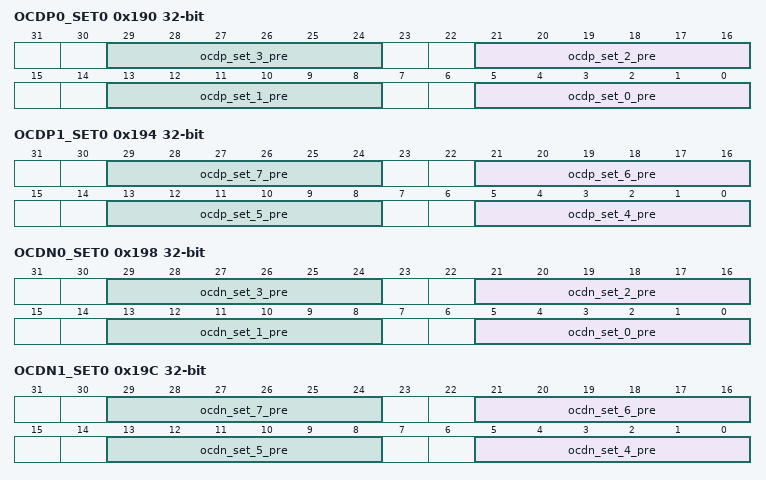
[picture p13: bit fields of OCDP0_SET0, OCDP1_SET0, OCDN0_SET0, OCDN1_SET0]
0x190 OCDP0_SET0
  [8n+5:8n] ocdp_set_{n}_pre (n=0..3) — P-OCD trimming set_{n}.
0x194 OCDP1_SET0
  [8n-27:8n-32] ocdp_set_{n}_pre (n=4..7) — P-OCD trimming set_{n}.
0x198 OCDN0_SET0
  [8n+5:8n] ocdn_set_{n}_pre (n=0..3) — N-OCD trimming set_{n}.
0x19C OCDN1_SET0
  [8n-27:8n-32] ocdn_set_{n}_pre (n=4..7) — N-OCD trimming set_{n}.
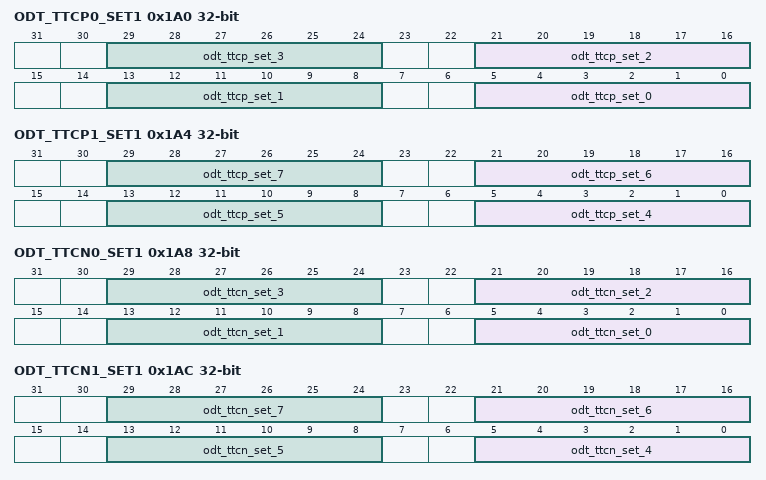
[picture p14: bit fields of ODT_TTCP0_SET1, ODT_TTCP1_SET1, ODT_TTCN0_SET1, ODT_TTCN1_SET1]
0x1A0 ODT_TTCP0_SET1
  [8n+5:8n] odt_ttcp_set_{n} (n=0..3) — P-ODT coarse trimming set_{n}.
0x1A4 ODT_TTCP1_SET1
  [8n-27:8n-32] odt_ttcp_set_{n} (n=4..7) — P-ODT coarse trimming set_{n}.
0x1A8 ODT_TTCN0_SET1
  [8n+5:8n] odt_ttcn_set_{n} (n=0..3) — N-ODT coarse trimming set_{n}.
0x1AC ODT_TTCN1_SET1
  [8n-27:8n-32] odt_ttcn_set_{n} (n=4..7) — N-ODT coarse trimming set_{n}.
0x1B0 OCDP0_SET1
  [8n+5:8n] ocdp_set_{n} (n=0..3) — P-OCD trimming set_{n}.
0x1B4 OCDP1_SET1
  [8n-27:8n-32] ocdp_set_{n} (n=4..7) — P-OCD trimming set_{n}.
0x1B8 OCDN0_SET1
  [8n+5:8n] ocdn_set_{n} (n=0..3) — N-OCD trimming set_{n}.
0x1BC OCDN1_SET1
  [8n-27:8n-32] ocdn_set_{n} (n=4..7) — N-OCD trimming set_{n}.
0x1C0 DQ_ODT_SEL_Set0
  [14:12] dq_1_ttcn_sel — N-ODT coarse tune selection for slice1 / slice3 DQ 000: odt_ttcn_set_0 ... 111: odt_ttcn_set_7
  [10:8] dq_0_ttcn_sel — N-ODT coarse tune selection for slice0 / slice2 DQ 000: odt_ttcn_set_0 ... 111: odt_ttcn_set_7
  [6:4] dq_1_ttcp_sel — P-ODT coarse tune selection for slice1 / slice3 DQ 000: odt_ttcp_set_0 ... 111: odt_ttcp_set_7
  [2:0] dq_0_ttcp_sel — P-ODT coarse tune selection for slice0 / slice2 DQ 000: odt_ttcp_set_0 ... 111: odt_ttcp_set_7
0x1C4 DQ_ODT_SEL_Set1
  fields as DQ_ODT_SEL_Set0
0x1C8 DQ_OCD_SEL_Set0
  [14:12] dq_1_ocdn_sel — N-OCD selection for slice1 / slice3 DQ 000: ocdn_set_0 ... 111: ocdn_set_7
  [10:8] dq_0_ocdn_sel — N-OCD selection for slice0 / slice2 DQ 000: ocdn_set_0 ... 111: ocdn_set_7
  [6:4] dq_1_ocdp_sel — P-OCD selection for slice1 / slice3 DQ 000: ocdp_set_0 ... 111: ocdp_set_7
  [2:0] dq_0_ocdp_sel — P-OCD selection for slice0 / slice2 DQ 000: ocdp_set_0 ... 111: ocdp_set_7
0x1CC DQ_OCD_SEL_Set1
  fields as DQ_OCD_SEL_Set0
0x1D0 DQS_P_ODT_SEL_Set0
  [14:12] dqs_p_1_ttcn_sel — N-ODT coarse tune selection for DQS[1] / DQS[3] 000: odt_ttcn_set_0 ... 111: odt_ttcn_set_7
  [10:8] dqs_p_0_ttcn_sel — N-ODT coarse tune selection for DQS[0] / DQS[2] 000: odt_ttcn_set_0 ... 111: odt_ttcn_set_7
  [6:4] dqs_p_1_ttcp_sel — P-ODT coarse tune selection for DQS[1] / DQS[3] 000: odt_ttcp_set_0 ... 111: odt_ttcp_set_7
  [2:0] dqs_p_0_ttcp_sel — P-ODT coarse tune selection for DQS[0] / DQS[2] 000: odt_ttcp_set_0 ... 111: odt_ttcp_set_7
0x1D4 DQS_P_ODT_SEL_Set1
  fields as DQS_P_ODT_SEL_Set0
0x1D8 DQS_N_ODT_SEL_Set0
  [14:12] dqs_n_1_ttcn_sel — N-ODT coarse tune selection for DQS#[1] / DQS#[3] 000: odt_ttcn_set_0 ... 111: odt_ttcn_set_7
  [10:8] dqs_n_0_ttcn_sel — N-ODT coarse tune selection for DQS#[0] / DQS#[2] 000: odt_ttcn_set_0 ... 111: odt_ttcn_set_7
  [6:4] dqs_n_1_ttcp_sel — P-ODT coarse tune selection for DQS#[1] / DQS#[3] 000: odt_ttcp_set_0 ... 111: odt_ttcp_set_7
  [2:0] dqs_n_0_ttcp_sel — P-ODT coarse tune selection for DQS#[0] / DQS#[2] 000: odt_ttcp_set_0 ... 111: odt_ttcp_set_7
0x1DC DQS_N_ODT_SEL_Set1
  fields as DQS_N_ODT_SEL_Set0
0x1E0 DQS_OCD_SEL_Set0
  [30:28] dqs_n_1_ocdn_sel — N-OCD selection for DQS#[1] / DQS#[3] 000: ocdn_set_0 ... 111: ocdn_set_7
  [26:24] dqs_n_0_ocdn_sel — N-OCD selection for DQS#[0] / DQS#[2] 000: ocdn_set_0 ... 111: ocdn_set_7
  [22:20] dqs_n_1_ocdp_sel — P-OCD selection for DQS#[1] / DQS#[3] 000: ocdp_set_0 ... 111: ocdp_set_7
  [18:16] dqs_n_0_ocdp_sel — P-OCD selection for DQS#[0] / DQS#[2] 000: ocdp_set_0 ... 111: ocdp_set_7
  [14:12] dqs_p_1_ocdn_sel — N-OCD selection for DQS[1] / DQS[3] 000: ocdn_set_0 ... 111: ocdn_set_7
  [10:8] dqs_p_0_ocdn_sel — N-OCD selection for DQS[0] / DQS[2] 000: ocdn_set_0 ... 111: ocdn_set_7
  [6:4] dqs_p_1_ocdp_sel — P-OCD selection for DQS[1] / DQS[3] 000: ocdp_set_0 ... 111: ocdp_set_7
  [2:0] dqs_p_0_ocdp_sel — P-OCD selection for DQS[0] / DQS[2] 000: ocdp_set_0 ... 111: ocdp_set_7
0x1E4 DQS_OCD_SEL_Set1
  fields as DQS_OCD_SEL_Set0
0x1E8 CKE_OCD_SEL
  [14:12] cke_1_ocdn_sel — N-OCD selection for CKE_1 (no use) 000: ocdn_set_0 ... 111: ocdn_set_7
  [10:8] cke_1_ocdp_sel — P-OCD selection for CKE_1 (no use) 000: ocdp_set_0 ... 111: ocdp_set_7
  [6:4] cke_ocdn_sel — N-OCD selection for CKE 000: ocdn_set_0 ... 111: ocdn_set_7
  [2:0] cke_ocdp_sel — P-OCD selection for CKE 000: ocdp_set_0 ... 111: ocdp_set_7
0x1EC ADR_OCD_SEL
  [30:28] cs_1_ocdn_sel — N-OCD selection for CS_1 000: ocdn_set_0 ... 111: ocdn_set_7
  [26:24] cs_1_ocdp_sel — P-OCD selection for CS_1 000: ocdp_set_0 ... 111: ocdp_set_7
  [14:12] cs_ocdn_sel — N-OCD selection for CS 000: ocdn_set_0 ... 111: ocdn_set_7
  [10:8] cs_ocdp_sel — P-OCD selection for CS 000: ocdp_set_0 ... 111: ocdp_set_7
0x1F0 CK_OCD_SEL
  [30:28] ck_n_1_ocdn_sel — N-OCD selection for DCK#[1] 000: ocdn_set_0 ... 111: ocdn_set_7
  [26:24] ck_n_0_ocdn_sel — N-OCD selection for DCK#[0] 000: ocdn_set_0 ... 111: ocdn_set_7
  [22:20] ck_n_1_ocdp_sel — P-OCD selection for DCK#[1] 000: ocdp_set_0 ... 111: ocdp_set_7
  [18:16] ck_n_0_ocdp_sel — P-OCD selection for DCK#[0] 000: ocdp_set_0 ... 111: ocdp_set_7
  [14:12] ck_p_1_ocdn_sel — N-OCD selection for DCK[1] 000: ocdn_set_0 ... 111: ocdn_set_7
  [10:8] ck_p_0_ocdn_sel — N-OCD selection for DCK[0] 000: ocdn_set_0 ... 111: ocdn_set_7
  [6:4] ck_p_1_ocdp_sel — P-OCD selection for DCK[1] 000: ocdp_set_0 ... 111: ocdp_set_7
  [2:0] ck_p_0_ocdp_sel — P-OCD selection for DCK[0] 000: ocdp_set_0 ... 111: ocdp_set_7
0x1F4 PAD_BUS_0
  [31] en_dcc — enable O_DCC output of CLK pad
  [30] pd_ck — Rx power down of CLK pad
  [29] en_dmyi — enable dummy current of of REFZQ pad
  [28] vref_sel — VREF SEL for VREFZQ pad When REFZQ.VREF_SEL = 1'b1,use resistor voltage divider to calibrate R480Ohm, when vref_sel = 1'b0, use bandgap voltage divider to calibrate R480 (Useless in RLE1080)
  [27] vref_range — VREF VREF_RANGE for VREF_CA pad 1'b1: 44% - 59% 1'b0: 38% - 53%
  [26:21] vref_s — VREF S for VREF_CA pad Control Vref voltage with vref_range, and add 1% voltage when add 1 level
  [20:19] vref_currentsel — Connect to CLKPG.PEAKING_EN
  [18] vref_pd — VREF pd for VREF_CA pad Power down Vref. zq_pd = 1 when use external Vref, zq_pad = 0 when use internal Vref
  [17:0] pad_bus_0 — [17:16]: Rx IBIAS_SEL for DQ/DQS/CLK pads [15:14]: No use [13:12]: No use [11:9]: slice3 DQS current selection for PUPD4 [8:6]: slice2 DQS current selection for PUPD4 [5:3]: slice1 DQS current selection for PUPD4 [2:0]: slice0 DQS current selection for PUPD4
0x1F8 PAD_BUS_1
  [31] pd_ck_1 — Rx power down of CLK_1 pad
  [15] vref_range_4 — VREF VREF_RANGE for normal Command/Address(CA) VREF pad 1'b1: 0.5% - 64.5% 1'b0: 28% - 92% (Useless in RLE1080)
  [14:9] vref_s_4 — VREF S for normal CA VREF pad Control Vref voltage with vref_range, and add 1% voltage when add 1 level (Useless in RLE1080)
  [8] vref_pd_4 — VREF pd for normal CA VREF pad (Useless in RLE1080)
  [6] zq_power_down
  [5:0] pad_bus_1 — [3:0]: No use [4]: No Use [5]: No Use
0x1FC PAD_BUS_2
  [31] vref_range_3 — VREF VREF_RANGE for normal byte-3 VREF pad 1'b1: 0.5% - 64.5% 1'b0: 28% - 92% (Useless in RLE1080)
  [30:25] vref_s_3 — VREF S for normal byte-3 VREF pad Control Vref voltage with vref_range, and add 1% voltage when add 1 level (Useless in RLE1080)
  [8n] vref_pd_{n} (n=0..3) — VREF pd for normal byte-{n} VREF pad
  [23] vref_range_2 — VREF VREF_RANGE for normal byte-2 VREF pad 1'b1: 0.5% - 64.5% 1'b0: 28% - 92% (Useless in RLE1080)
  [22:17] vref_s_2 — VREF S for normal byte-2 VREF pad Control Vref voltage with vref_range, and add 1% voltage when add 1 level (Useless in RLE1080)
  [15] vref_range_1 — VREF VREF_RANGE for normal byte-1 VREF pad 1'b1: 0.5% - 64.5% 1'b0: 28% - 92% (Useless in RLE1080)
  [14:9] vref_s_1 — VREF S for normal byte-1 VREF pad Control Vref voltage with vref_range, and add 1% voltage when add 1 level (Useless in RLE1080)
  [7] vref_range_0 — VREF VREF_RANGE for normal byte-0 VREF pad 1'b1: 44% - 59% 1'b0: 38% - 53%
  [6:1] vref_s_0 — VREF S for normal byte-0 VREF pad Control Vref voltage with vref_range, and add 1% voltage when add 1 level
0x200 ZQ_TRIM
  [0] r480_trim — control R480 calibration trim 1'b1 : r480 result -1
0x204 OCD_SEL_0
  [30-8n:28-8n] adr{n:02}_ocdn_sel (n=0..3) — N-OCD selection for A{n} 000: ocdn_set_0 ... 111: ocdn_set_7
  [26-8n:24-8n] adr{n:02}_ocdp_sel (n=0..3) — P-OCD selection for A{n} 000: ocdp_set_0 ... 111: ocdp_set_7
0x208 OCD_SEL_1
  [62-8n:60-8n] adr{n:02}_ocdn_sel (n=4..7) — N-OCD selection for A{n} 000: ocdn_set_0 ... 111: ocdn_set_7
  [58-8n:56-8n] adr{n:02}_ocdp_sel (n=4..7) — P-OCD selection for A{n} 000: ocdp_set_0 ... 111: ocdp_set_7
0x20C OCD_SEL_2
  [94-8n:92-8n] adr{n:02}_ocdn_sel (n=8..11) — N-OCD selection for A{n} 000: ocdn_set_0 ... 111: ocdn_set_7
  [90-8n:88-8n] adr{n:02}_ocdp_sel (n=8..11) — P-OCD selection for A{n} 000: ocdp_set_0 ... 111: ocdp_set_7
0x210 OCD_SEL_3
  [126-8n:124-8n] adr{n}_ocdn_sel (n=12..15) — N-OCD selection for A{n} 000: ocdn_set_0 ... 111: ocdn_set_7
  [122-8n:120-8n] adr{n}_ocdp_sel (n=12..15) — P-OCD selection for A{n} 000: ocdp_set_0 ... 111: ocdp_set_7
0x214 OCD_SEL_4
  [30:28] adr16_ocdn_sel — N-OCD selection for A16 000: ocdn_set_0 ... 111: ocdn_set_7
  [26:24] adr16_ocdp_sel — P-OCD selection for A16 000: ocdp_set_0 ... 111: ocdp_set_7
  [22:20] adr_ext_4_ocdn_sel — N-OCD selection for AD1_4 000: ocdn_set_0 ... 111: ocdn_set_7
  [18:16] adr_ext_4_ocdp_sel — P-OCD selection for AD1_4 000: ocdp_set_0 ... 111: ocdp_set_7
  [14:12] adr_ext_5_ocdn_sel — N-OCD selection for AD1_5 000: ocdn_set_0 ... 111: ocdn_set_7
  [10:8] adr_ext_5_ocdp_sel — P-OCD selection for AD1_5 000: ocdp_set_0 ... 111: ocdp_set_7
  [6:4] ba0_ocdn_sel — N-OCD selection for BA0 000: ocdn_set_0 ... 111: ocdn_set_7
  [2:0] ba0_ocdp_sel — P-OCD selection for BA0 000: ocdp_set_0 ... 111: ocdp_set_7
0x218 OCD_SEL_5
  [30:28] ba1_ocdn_sel — N-OCD selection for BA1 000: ocdn_set_0 ... 111: ocdn_set_7
  [26:24] ba1_ocdp_sel — P-OCD selection for BA1 000: ocdp_set_0 ... 111: ocdp_set_7
  [22:20] ba2_ocdn_sel — N-OCD selection for BA2 000: ocdn_set_0 ... 111: ocdn_set_7
  [18:16] ba2_ocdp_sel — P-OCD selection for BA2 000: ocdp_set_0 ... 111: ocdp_set_7
  [14:12] ras_ocdn_sel — N-OCD selection for RASN 000: ocdn_set_0 ... 111: ocdn_set_7
  [10:8] ras_ocdp_sel — P-OCD selection for RASN 000: ocdp_set_0 ... 111: ocdp_set_7
  [6:4] cas_ocdn_sel — N-OCD selection for CASN 000: ocdn_set_0 ... 111: ocdn_set_7
  [2:0] cas_ocdp_sel — P-OCD selection for CASN 000: ocdp_set_0 ... 111: ocdp_set_7
